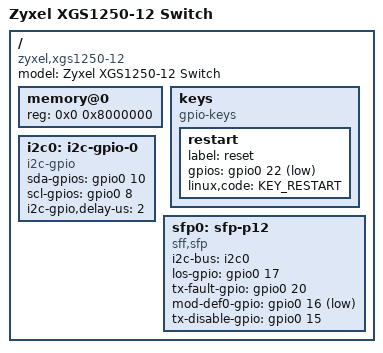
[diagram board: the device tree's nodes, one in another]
// SPDX-License-Identifier: GPL-2.0-or-later
/dts-v1/;

#include "rtl930x.dtsi"

#include <dt-bindings/input/input.h>
#include <dt-bindings/gpio/gpio.h>

/ {
	compatible = "zyxel,xgs1250-12", "realtek,rtl9300-soc";
	model = "Zyxel XGS1250-12 Switch";

	// mw.l 0xb8003308 0x00200000 active low toggles PHY reset <= GPIO21
	memory@0 {
		device_type = "memory";
		reg = <0x0 0x8000000>;
	};

	keys {
		compatible = "gpio-keys";

		restart {
			label = "reset";
			gpios = <&gpio0 22 GPIO_ACTIVE_LOW>;
			linux,code = <KEY_RESTART>;
		};
	};

	/* i2c of the SFP cage: port 12 */
	i2c0: i2c-gpio-0 {
		compatible = "i2c-gpio";
		sda-gpios = <&gpio0 10 (GPIO_ACTIVE_HIGH | GPIO_OPEN_DRAIN)>;
		scl-gpios = <&gpio0 8 (GPIO_ACTIVE_HIGH | GPIO_OPEN_DRAIN)>;
		i2c-gpio,delay-us = <2>;
		#address-cells = <1>;
		#size-cells = <0>;
	};

	sfp0: sfp-p12 {
		compatible = "sff,sfp";
		i2c-bus = <&i2c0>;
		los-gpio = <&gpio0 17 GPIO_ACTIVE_HIGH>;
		tx-fault-gpio = <&gpio0 20 GPIO_ACTIVE_HIGH>;
		mod-def0-gpio = <&gpio0 16 GPIO_ACTIVE_LOW>;
		tx-disable-gpio = <&gpio0 15 GPIO_ACTIVE_HIGH>;
	};

};
